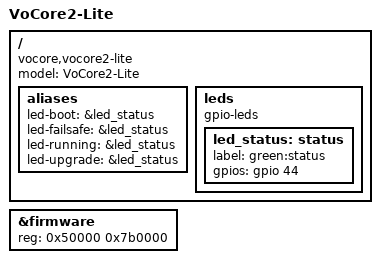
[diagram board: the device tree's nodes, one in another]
#include "mt7628an_vocore_vocore2.dtsi"

/ {
	compatible = "vocore,vocore2-lite", "vocore,vocore2", "mediatek,mt7628an-soc";
	model = "VoCore2-Lite";

	aliases {
		led-boot = &led_status;
		led-failsafe = &led_status;
		led-running = &led_status;
		led-upgrade = &led_status;
	};

	leds {
		compatible = "gpio-leds";

		led_status: status {
			label = "green:status";
			gpios = <&gpio 44 GPIO_ACTIVE_HIGH>;
		};
	};
};

&firmware {
	reg = <0x50000 0x7b0000>;
};
